# NUC400_v1 register map
File version: 1.0
Registers are 32-bit, read-write, reset 0x0 unless marked. A register's access mark holds for its fields unless they carry their own. Offsets are from the block's base; [hi:lo] are bit positions; {n}, {i} and the like mark numbered series; 'fields as' and 'values as' point back to an identical list.

## ADC — ADC Register Map
Base 0x40043000
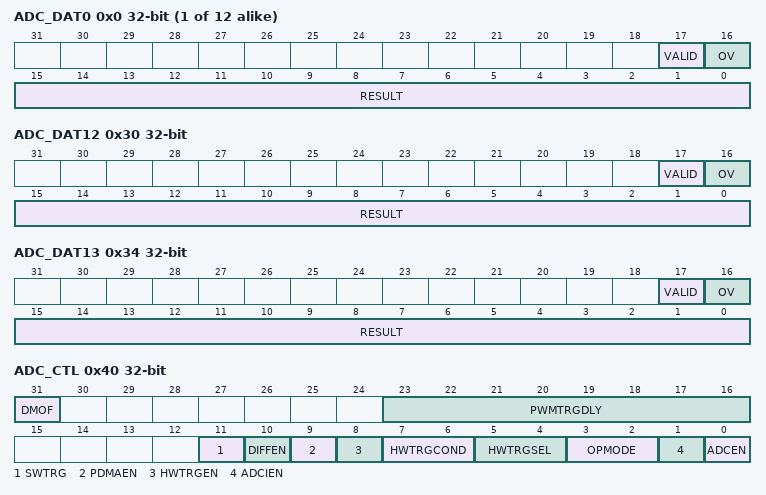
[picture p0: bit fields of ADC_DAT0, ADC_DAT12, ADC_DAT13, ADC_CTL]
{0x0+4i} ADC_DAT{i} ro (i=0..11) — ADC Data Register {i}
  [17] VALID — Valid Flag (Read Only). This bit is set to 1 when corresponding channel analog input conversion is completed and cleared by hardware after ADC_DAT register is read.
    0=Data in RESULT (ADC_DATx[15:0]) bits is not valid; 1=Data in RESULT (ADC_DATx[15:0]) bits is valid
  [16] OV — Overrun Flag (Read Only). If converted data in RESULT[15:0] has not been read before new conversion result is loaded to this register, OV is set to 1 and previous conversion result is gone. It is cleared by hardware after ADC_DAT register is read.
    0=Data in RESULT (ADC_DATx[15:0]) is recent conversion result; 1=Data in RESULT (ADC_DATx[15:0]) is overwrite
  [15:0] RESULT — A/D Conversion Result. This field contains conversion result of ADC. When DMOF (ADC_CTL[31]) bit is set to 0, 12-bit ADC conversion result with unsigned format will be filled in RESULT[11:0] and zero will be filled in RESULT[15:12]. When DMOF (ADC_CTL[31]) bit set to 1, 12-bit ADC conversion result with 2'complement format will be filled in RESULT[11:0] and signed bits to will be filled in RESULT[15:12].
0x30 ADC_DAT12 ro — ADC Data Register 12 (for Band-gap Voltage)
  fields as ADC_DAT0
0x34 ADC_DAT13 ro — ADC Data Register 13 (for Temperature Sensor)
  fields as ADC_DAT0
0x40 ADC_CTL — ADC Control Register
  [31] DMOF — ADC Differential Input Mode Output Format
    0=A/D conversion result will be filled in RESULT (ADC_DATx[15:0]) registers with unsigned format; 1=A/D conversion result will be filled in RESULT (ADC_DATx[15:0]) registers with 2'complement format
  [23:16] PWMTRGDLY — PWM Trigger Delay Time. Setting this field will delay ADC start conversion time after PWM trigger comes. PWM trigger delay time is 4 * system clock * PWMTRGDLY (ADC_CTL[23:16])
  [11] SWTRG — A/D Conversion Start. The SWTRG (ADC_CTL[11]) bit can be set to 1 from two sources: software and hardware trigger. The SWTRG (ADC_CTL[11]) bit will be cleared to 0 by hardware automatically at the ends of single mode and single-cycle scan mode. In continuous scan mode, A/D conversion is continuously performed until software write 0 to this bit or chip reset.
    0=Conversion stopped and A/D converter enter idle state; 1=Conversion start
  [10] DIFFEN — Differential Input Mode Enable Bit. In differential input mode, only the even number of the two corresponding channels needs to be enabled in ADCHER (ADC_CHEN[11:0]). The conversion result will be placed to the corresponding data register of the enabled channel.
    0=Single-end analog input mode; 1=Differential analog input mode
  [9] PDMAEN — PDMA Transfer Enable Bit. When A/D conversion is completed, the converted data is loaded into ADC_DATx, software can enable this bit to generate a PDMA data transfer request. When PDMAEN (ADC_CTL[9]) is set to 1, software must set ADCIEN (ADC_CTL[1]) bit to 0 to disable interrupt.
    0=PDMA data transfer Disabled; 1=PDMA data transfer in ADC_DATx Enabled
  [8] HWTRGEN — External Hardware Trigger Enable Bit. Enable or disable hardware triggering of A/D conversion. The hardware trigger source include external pin (STADC) or PWM trigger which is controlled by HWTRGSEL (ADC_CTL[5:4]) register. ADC hardware trigger function is only supported in single-cycle scan mode.
    0=Disabled; 1=Enabled
  [7:6] HWTRGCOND — External Pin Trigger Conditions. These two bits decide external pin (STADC) trigger event. The signal must be kept at stable state at least 8 system clocks for level trigger and 4 system clocks at high and low state for edge trigger.
    0=Low level; 1=High level; 2=Falling edge; 3=Rising edge
  [5:4] HWTRGSEL — External Hardware Trigger Source. Software should disable HWTRGCOND (ADC_CTL[8]) and SWTRG (ADC_CTL[11]) before changing HWTRGSEL (ADC_CTL[5:4]). In hardware trigger mode, the SWTRG (ADC_CTL[11]) bit is set by hardware trigger source.
    0=A/D conversion is started by external pin (STADC); 3=PWM0 or PWM1 trigger condition is matched
  [3:2] OPMODE — ADC Operation Mode. When changing the operation mode, software should disable SWTRG (ADC_CTL[11]) bit firstly.
    0=Single conversion; 2=Single-cycle scan; 3=Continuous scan
  [1] ADCIEN — ADC Interrupt Enable Bit. A/D conversion end interrupt request is generated if ADCIEN (ADC_CTL[1]) bit is set to 1.
    0=ADC interrupt function Disabled; 1=ADC interrupt function Enabled
  [0] ADCEN — ADC Enable Bit. Before disabling ADC clock, this bit should be cleared to 0 by software.
    0=ADC analog circuit Disabled; 1=ADC analog circuit Enabled
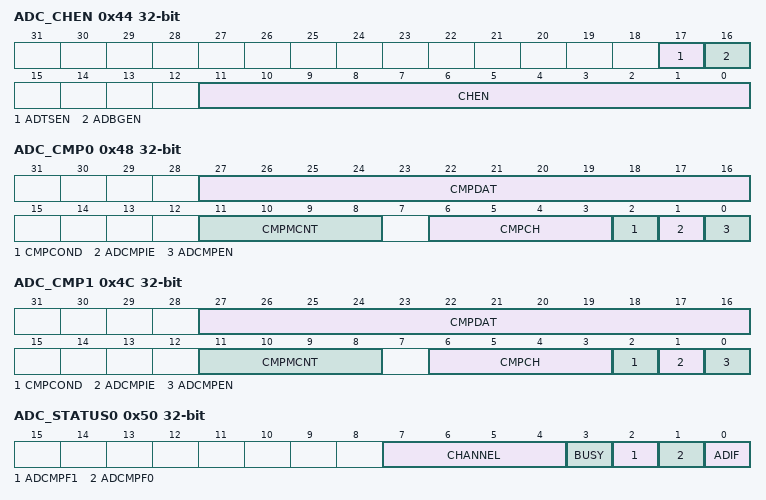
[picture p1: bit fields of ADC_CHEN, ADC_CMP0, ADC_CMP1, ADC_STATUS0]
0x44 ADC_CHEN — ADC Channel Enable Control Register
  [17] ADTSEN — Internal Temperature Sensor Selection. ADC can only work at Single mode when software selects the temperature sensor voltage as the analog input source of ADC.
    0=Internal temperature sensor is not selected to be the analog input source of ADC; 1=Internal temperature sensor is selected to be the analog input source of ADC
  [16] ADBGEN — Internal Band-Gap Selection. ADC can only work at Single mode when software selects the band-gap voltage as the analog input source of ADC
    0=Internal band-gap is not selected to be the analog input source of ADC; 1=Internal band-gap is selected to be the analog input source of ADC
  [11:0] CHEN — Analog Input Channel Enable Bit. Set CHEN (ADC_CHEN[11:0]) to enable the corresponding analog input channel (ADC0_CH1 ~ ADC0_CH11). If DIFFEN bit is set to 1, only the even number channels need to be enabled
    0=ADC input channel Disabled; 1=ADC input channel Enabled
0x48 ADC_CMP0 — ADC Compare Register 0
  [27:16] CMPDAT — Compared Data. When DMOF (ADC_CTL[31]) bit is set to 0, ADC comparator compares CMPDAT (ADC_CTL[27:16]) with conversion result with unsigned format. CMPDAT (ADC_CTL[27:16]) should be filled in unsigned format. When DMOF (ADC_CTL[31]) bit is set to 1, ADC comparator compares CMPDAT (ADC_CTL[27:16]) with conversion result with 2'complement format. CMPDAT (ADC_CTL[27:16]) should be filled in 2'complement format.
  [11:8] CMPMCNT — Compare Match Count. When the specified ADC channel analog conversion result matches the compare condition defined by CMPCOND (ADC_CMPx[2]), the internal match counter will increase 1. When the internal counter reaches the value to CMPMCNT (ADC_CMPx[11:8]) + 1, the ADCMPFx (ADC_STATUS0[2:1]) bit will be set.
  [6:3] CMPCH — Compare Channel Selection
    {v}=Channel {v} conversion result is selected to be compared (v=0..11); 12=band-gap voltage result is selected to be compared; 13=temperature sensor conversion result is selected to be compared
  [2] CMPCOND — Compare Condition. Note: When the internal counter reaches the value to CMPMCNT (ADC_CMPx[11:8]) + 1, the ADCMPFx (ADC_STATUS0[2:1]) bit will be set.
    0=Set the compare condition as that when a 12-bit A/D conversion result is less than the 12-bit CMPDAT (ADC_CMPx[27:16]), the internal match counter will increase one; 1=Set the compare condition as that when a 12-bit A/D conversion result is greater or equal to the 12-bit CMPDAT (ADC_CMPx[27:16]), the internal match counter will increase one
  [1] ADCMPIE — Compare Interrupt Enable Bit. If the compare function is enabled and the compare condition matches the setting of CMPCOND (ADC_CMPx[2]) and CMPMCNT(ADC_CMPx[11:8]), ADCMPFx (ADC_STATUS0[2:1]) bit will be asserted, in the meanwhile, if ADCMPIE (ADC_CMPx[1])is set to 1, a compare interrupt request is generated.
    0=Compare function interrupt Disabled; 1=Compare function interrupt Enabled
  [0] ADCMPEN — Compare Enable Bit. Set this bit to 1 to enable ADC controller to compare CMPDAT (ADC_CMPx[27:16]) with the conversion result of the channel specified by CMPCH (ADC_CMPx[6:3]) when the conversion data of the specified channel is loaded into ADC_DATx register.
    0=Compare function Disabled; 1=Compare function Enabled
0x4C ADC_CMP1 — ADC Compare Register 1
  fields as ADC_CMP0
0x50 ADC_STATUS0 — ADC Status Register 0
  [7:4] CHANNEL ro — Current Conversion Channel (Read Only)
  [3] BUSY ro — BUSY/IDLE (Read Only). This bit is mirror of as SWTRG (ADC_CTL[11]) bit.
    0=ADC is in idle state; 1=ADC is doing conversion
  [2] ADCMPF1 — Compare Flag. When the selected channel A/D conversion result meets setting condition in ADCMPR1 then this bit is set to 1. And it is cleared by writing 1 to self.
    0=Conversion result in ADC_DATx does not meet ADCMPR1 setting; 1=Conversion result in ADC_DATx meets ADCMPR1 setting
  [1] ADCMPF0 — Compare Flag. When the selected channel A/D conversion result meets setting condition in ADCMPR0 then this bit is set to 1. And it is cleared by writing 1 to self.
    0=Conversion result in ADC_DATx does not meet ADCMPR0 setting; 1=Conversion result in ADC_DATx meets ADCMPR0 setting
  [0] ADIF — ADC Interrupt Flag. A status flag that indicates the end of A/D conversion. ADIF (ADC_STATUS0[0]) is set to 1 at these two conditions: 1. When A/D conversion ends in Single mode. 2. When A/D conversion ends on all specified channels in Scan mode. Note: This flag can be cleared by writing 1 to it.
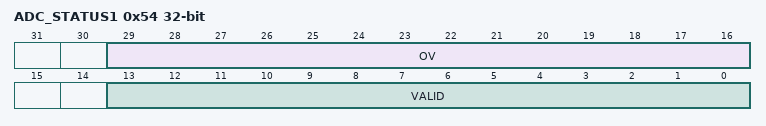
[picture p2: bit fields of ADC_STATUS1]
0x54 ADC_STATUS1 ro — ADC Status Register 1
  [29:16] OV — Overrun Flag (Read Only). It is a mirror to OV (ADC_DATx[16]) bit.
  [13:0] VALID — Data Valid Flag (Read Only). It is a mirror of VALID (ADC_DATx[17]) bit.
0x60 ADC_CURDAT ro — ADC PDMA Current Transfer Data Register
  [17:0] CURDAT — ADC PDMA Current Transfer Data Bit (Read Only). When PDMA transferring, read this register can monitor current PDMA transfer data.
